# nrf9230_enga_cellrf register map
Vendor: Nordic Semiconductor; Series: nRF92; File version: 1
CPU: CM0 r0p0, little endian, no MPU, no FPU, 2 interrupt priority bits, 33 interrupts
Registers are 32-bit, read-write, reset 0x0 unless marked. A register's access mark holds for its fields unless they carry their own. Offsets are from the block's base; [hi:lo] are bit positions; lines under a group give offsets from that group; {n}, {i} and the like mark numbered series; 'fields as' and 'values as' point back to an identical list.

## SENSORADC — Sensor Analog to Digital Converter
Base 0x46046000
0x00 TASKS_START wo — Start the ADC and prepare the result buffer in RAM.
  [0] TASKS_START
    1=Trigger task
0x04 TASKS_STOP wo — Stop the ADC and terminate any on-going conversion.
  [0] TASKS_STOP
    1=Trigger task
0x08 TASKS_SAMPLE wo — Start ADC sampling. Depending on the mode selected, one or more samples will be taken.
  [0] TASKS_SAMPLE
    1=Trigger task
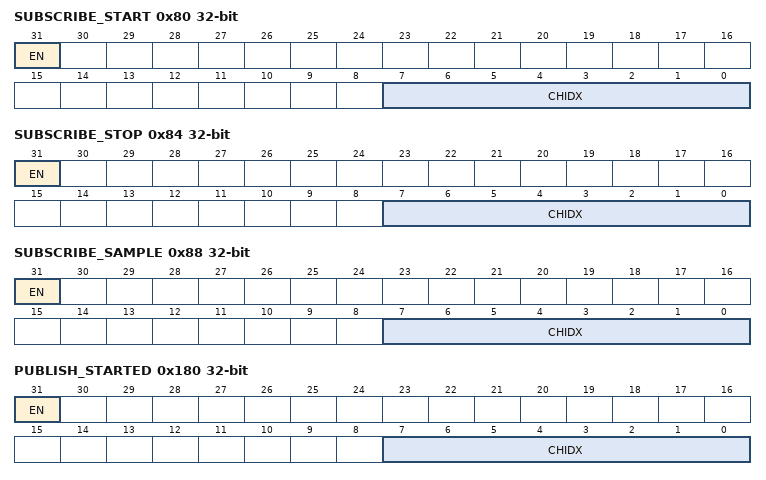
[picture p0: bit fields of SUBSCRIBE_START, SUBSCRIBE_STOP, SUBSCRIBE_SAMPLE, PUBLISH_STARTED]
0x80 SUBSCRIBE_START — Subscribe configuration for task START
  [31] EN
    0=Disabled (Disable subscription); 1=Enabled (Enable subscription)
  [7:0] CHIDX — DPPI channel that task START will subscribe to
0x84 SUBSCRIBE_STOP — Subscribe configuration for task STOP
  [31] EN
    values as SUBSCRIBE_START.EN
  [7:0] CHIDX — DPPI channel that task STOP will subscribe to
0x88 SUBSCRIBE_SAMPLE — Subscribe configuration for task SAMPLE
  [31] EN
    values as SUBSCRIBE_START.EN
  [7:0] CHIDX — DPPI channel that task SAMPLE will subscribe to
0x100 EVENTS_STARTED — The ADC has started.
  [0] EVENTS_STARTED
    0=NotGenerated (Event not generated); 1=Generated (Event generated)
0x104 EVENTS_STOPPED — The ADC has stopped.
  [0] EVENTS_STOPPED
    values as EVENTS_STARTED.EVENTS_STARTED
0x108 EVENTS_SAMPLEDONE — A single conversion has been completed and the corresponding result has been stored in RESULTN and RESULTP registers.
  [0] EVENTS_SAMPLEDONE
    values as EVENTS_STARTED.EVENTS_STARTED
0x10C EVENTS_AVERAGEDONE — The averaging has been completed and the corresponding, averaged result has been stored in AVERAGEN and AVERAGEP registers.
  [0] EVENTS_AVERAGEDONE
    values as EVENTS_STARTED.EVENTS_STARTED
0x110 EVENTS_DMANOTFULL — A result of last A/D conversion has been transferred to RAM and there is still space in RAM
  [0] EVENTS_DMANOTFULL
    values as EVENTS_STARTED.EVENTS_STARTED
0x114 EVENTS_DMADONE — A result of last A/D conversion has been transferred to RAM.
  [0] EVENTS_DMADONE
    values as EVENTS_STARTED.EVENTS_STARTED
0x118 EVENTS_DMAEND — The ADC has filled up the result buffer in RAM
  [0] EVENTS_DMAEND
    values as EVENTS_STARTED.EVENTS_STARTED
0x180 PUBLISH_STARTED — Publish configuration for event STARTED
  [31] EN
    0=Disabled (Disable publishing); 1=Enabled (Enable publishing)
  [7:0] CHIDX — DPPI channel that event STARTED will publish to
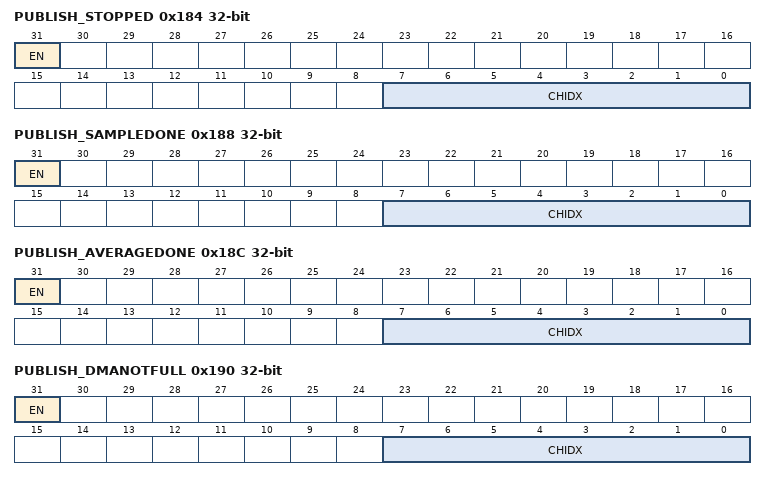
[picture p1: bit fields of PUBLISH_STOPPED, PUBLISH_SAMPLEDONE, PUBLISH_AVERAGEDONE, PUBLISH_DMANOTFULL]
0x184 PUBLISH_STOPPED — Publish configuration for event STOPPED
  [31] EN
    values as PUBLISH_STARTED.EN
  [7:0] CHIDX — DPPI channel that event STOPPED will publish to
0x188 PUBLISH_SAMPLEDONE — Publish configuration for event SAMPLEDONE
  [31] EN
    values as PUBLISH_STARTED.EN
  [7:0] CHIDX — DPPI channel that event SAMPLEDONE will publish to
0x18C PUBLISH_AVERAGEDONE — Publish configuration for event AVERAGEDONE
  [31] EN
    values as PUBLISH_STARTED.EN
  [7:0] CHIDX — DPPI channel that event AVERAGEDONE will publish to
0x190 PUBLISH_DMANOTFULL — Publish configuration for event DMANOTFULL
  [31] EN
    values as PUBLISH_STARTED.EN
  [7:0] CHIDX — DPPI channel that event DMANOTFULL will publish to
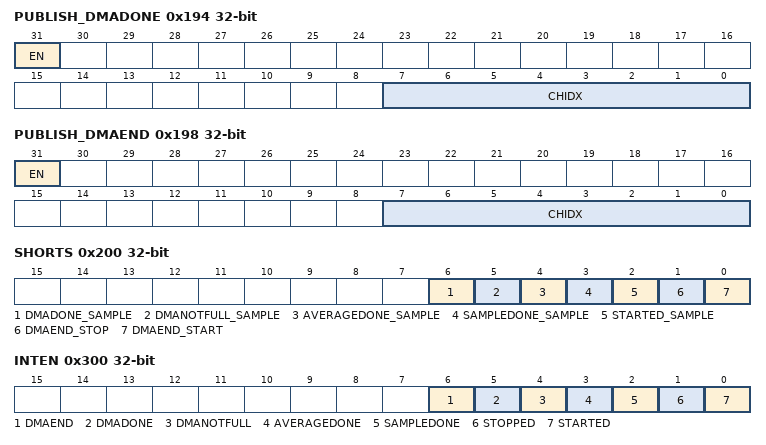
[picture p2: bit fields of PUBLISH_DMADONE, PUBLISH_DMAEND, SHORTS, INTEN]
0x194 PUBLISH_DMADONE — Publish configuration for event DMADONE
  [31] EN
    values as PUBLISH_STARTED.EN
  [7:0] CHIDX — DPPI channel that event DMADONE will publish to
0x198 PUBLISH_DMAEND — Publish configuration for event DMAEND
  [31] EN
    values as PUBLISH_STARTED.EN
  [7:0] CHIDX — DPPI channel that event DMAEND will publish to
0x200 SHORTS — Shortcuts between local events and tasks
  [all] fields
    0=Disabled (Disable shortcut); 1=Enabled (Enable shortcut)
  [6] DMADONE_SAMPLE — Shortcut between event DMADONE and task SAMPLE
  [5] DMANOTFULL_SAMPLE — Shortcut between event DMANOTFULL and task SAMPLE
  [4] AVERAGEDONE_SAMPLE — Shortcut between event AVERAGEDONE and task SAMPLE
  [3] SAMPLEDONE_SAMPLE — Shortcut between event SAMPLEDONE and task SAMPLE
  [2] STARTED_SAMPLE — Shortcut between event STARTED and task SAMPLE
  [1] DMAEND_STOP — Shortcut between event DMAEND and task STOP
  [0] DMAEND_START — Shortcut between event DMAEND and task START
0x300 INTEN — Enable or disable interrupt
  [all] fields
    0=Disabled; 1=Enabled
  [6] DMAEND — Enable or disable interrupt for event DMAEND
  [5] DMADONE — Enable or disable interrupt for event DMADONE
  [4] DMANOTFULL — Enable or disable interrupt for event DMANOTFULL
  [3] AVERAGEDONE — Enable or disable interrupt for event AVERAGEDONE
  [2] SAMPLEDONE — Enable or disable interrupt for event SAMPLEDONE
  [1] STOPPED — Enable or disable interrupt for event STOPPED
  [0] STARTED — Enable or disable interrupt for event STARTED
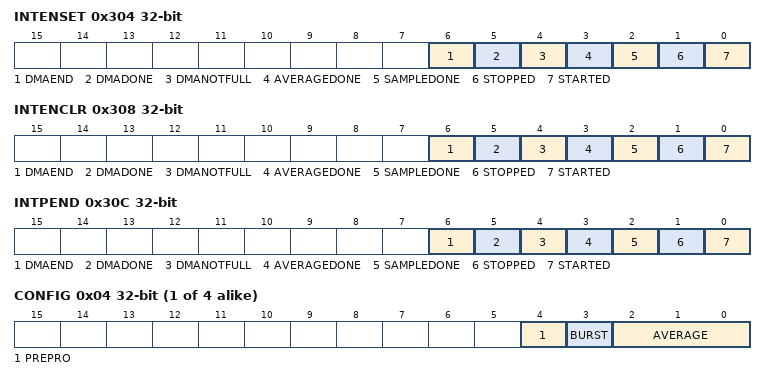
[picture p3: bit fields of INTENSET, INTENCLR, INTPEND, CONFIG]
0x304 INTENSET — Enable interrupt
  [all] fields
    on read: 0=Disabled (Read: Disabled); 1=Enabled (Read: Enabled) | on write: 1=Set (Enable)
  [6] DMAEND — Write '1' to enable interrupt for event DMAEND
  [5] DMADONE — Write '1' to enable interrupt for event DMADONE
  [4] DMANOTFULL — Write '1' to enable interrupt for event DMANOTFULL
  [3] AVERAGEDONE — Write '1' to enable interrupt for event AVERAGEDONE
  [2] SAMPLEDONE — Write '1' to enable interrupt for event SAMPLEDONE
  [1] STOPPED — Write '1' to enable interrupt for event STOPPED
  [0] STARTED — Write '1' to enable interrupt for event STARTED
0x308 INTENCLR — Disable interrupt
  [all] fields
    on read: 0=Disabled (Read: Disabled); 1=Enabled (Read: Enabled) | on write: 1=Clear (Disable)
  [6] DMAEND — Write '1' to disable interrupt for event DMAEND
  [5] DMADONE — Write '1' to disable interrupt for event DMADONE
  [4] DMANOTFULL — Write '1' to disable interrupt for event DMANOTFULL
  [3] AVERAGEDONE — Write '1' to disable interrupt for event AVERAGEDONE
  [2] SAMPLEDONE — Write '1' to disable interrupt for event SAMPLEDONE
  [1] STOPPED — Write '1' to disable interrupt for event STOPPED
  [0] STARTED — Write '1' to disable interrupt for event STARTED
0x30C INTPEND ro — Pending interrupts
  [all] fields
    on read: 0=NotPending (Read: Not pending); 1=Pending (Read: Pending)
  [6] DMAEND — Read pending status of interrupt for event DMAEND
  [5] DMADONE — Read pending status of interrupt for event DMADONE
  [4] DMANOTFULL — Read pending status of interrupt for event DMANOTFULL
  [3] AVERAGEDONE — Read pending status of interrupt for event AVERAGEDONE
  [2] SAMPLEDONE — Read pending status of interrupt for event SAMPLEDONE
  [1] STOPPED — Read pending status of interrupt for event STOPPED
  [0] STARTED — Read pending status of interrupt for event STARTED
0x400 STATUS ro — ADC status
  [2:0] CURRSTATE — Current FSM state. More and less for debugging.
    0=Stopped (Unspecified); 1=Started (Unspecified); 2=Idle (Unspecified); 3=Settling (Unspecified); 4=Conversion (Unspecified); 5=Result (Unspecified)
0x500 ENABLE — Set value for output signal Enable
  [0] ENABLE — This register has no other function than defining the value on enable output. Check the usage of this signal from integration level.
    0=Disabled; 1=Enabled
0x504 ICTRL — Adjust charge current
  [3:0] ICTRL — Adjust charge current (thermometer coding).
    0=Min (Capacitor charge current is 0 * Uin/R (reset value)); 6=Default (Capacitor charge current is 6/12 * Uin/R (default)); 15=Max (Capacitor charge current is 15/12 * Uin/R)
0x508 SETTLINGTIME — Settling time selection
  [2:0] TIME — Settling time selection.
    0=Time1us (1 us (123 * 1 core clock cycles)); 1=Time2us (2 us (123 * 2 core clock cycles)); 2=Time4us (4 us (123 * 4 core clock cycles)); 3=Time8us (8 us (123 * 8 core clock cycles)); 4=Time16us (16 us (123 * 16 core clock cycles)); 5=Time32us (32 us (123 * 32 core clock cycles)); 6=Time64us (64 us (123 * 64 core clock cycles)); 7=Time128us (128 us (123 * 128 core clock cycles))
0x50C CONVCYCLES — Conversion cycles (i.e. accuracy)
  [15:0] CYCLES — Conversion cycles (i.e. accuracy).
    0xFFFF=Max (65535: 65535 core clock cycles)
0x510 CONVMODE — Conversion mode selection
  [1:0] MODE — Conversion mode selection.
    0=One-shot mode; 1=Pure one-shot mode; 2=Continuous mode
{0x514+8i} CH[{i}] (i=0..3) group — Unspecified
  0x00 INSEL — Description cluster: Input pin selection for CH[n]
    [15:0] INSEL — Input pin selection for channel n. Please only use values listed here. Other values will cause two inputs to be weakly shorted together.
      0=Nothing is connected; 1=VinAo0; 2=VinAo1; 4=VinAo2; 8=VinAo3; 16=Vin0; 32=Vin1; 64=Vin2; 128=Vin3; 0x200=Vref2 (750 mV); 0x400=Vref0 = (300 mV); 0x800=Vref1 = (600 mV); 0x1000=ATB0_1V8; 0x2000=ATB1_1V8; 0x4000=WATB2_1V8; 0x8000=WATB3_1V8
  0x04 CONFIG — Description cluster: Configuration for CH[n]
    [4] PREPRO — Pre-processing mode. When the pre-processing mode is selected, P results are pre-processed before being stored in RESULTP/AVERAGEP register.
      0=Normal operation; 1=Pre-processing mode
    [3] BURST — Burst mode. Reduces settling time to a minimum between conversions when averaging or continuous mode is enabled.
      0=Normal operation; 1=Burst mode enabled
    [2:0] AVERAGE — Averaging configuration.
      0=Disabled (Averaging disabled); 1=Averaging by 2; 2=Averaging by 4; 3=Averaging by 8; 4=Averaging by 16; 5=Averaging by 32; 6=Averaging by 64; 7=Averaging by 128
0x554 RESULTN ro — Result N of last A/D conversion
  [15:0] RESULT — Result N of last A/D conversion. The value is updated for every completed conversion. The value is in unsigned format.
0x558 RESULTP ro — Result P of last A/D conversion
  [15:0] RESULT — Result P of last A/D conversion. The value is updated for every completed conversion. The value is in unsigned format.
0x55C AVERAGEN ro — Result N of last averaged A/D conversion
  [15:0] AVERAGE — Result N of last averaged A/D conversion. The value is updated for every completed averaged conversion. The value is in unsigned format.
0x560 AVERAGEP ro — Result P of last averaged A/D conversion
  [15:0] AVERAGE — Result P of last averaged A/D conversion. The value is updated for every completed averaged conversion. The value is in unsigned format.
0x564 RESETCONFIG — Reset configuration
  [0] CONFIG — Backdoor for core part reset.
    0=NoEffect; 1=CoreReset (Debug only: Core is reset asynchronously when IP is not active. Note that this can cause reset doman crossing (RDC) violation.)
0x568 SPARE
  [3:0] SPARE
0x56C ATB0CFG — Configuration for ATB 0 connection. Access to this register is only allowed when dftEnable input is 1.
  [0] ATB0CFG — Configuration for ATB 0 connection.
    0=Nothing is connected to ATB0_1V8; 1=Vref1 is connected to ATB0_1V8
0x570 ATB1CFG — Configuration for ATB 1 connection. Access to this register is only allowed when dftEnable input is 1.
  [2:0] ATB1CFG — Configuration for ATB 1 connection.
    {v}=Nothing{v} (Nothing is connected to ATB1_1V8) (v=0..4); 5=Vref1 (Connect Vref1 to ATB1_1V8); 6=Vc (Connect Vc to ATB1_1V8); 7=Vr (Connect Vr to ATB1_1V8)
0x574 DTB0CFG — Configuration for DTB 0 connection. Access to this register is only allowed when dftEnable input is 1.
  [0] DTB0CFG — Configuration for DTB 0 connection.
    0=Nothing is connected to DTB_SENSORADC_0V8[0]; 1=FOUT is connected to DTB_SENSORADC_0V8[0]
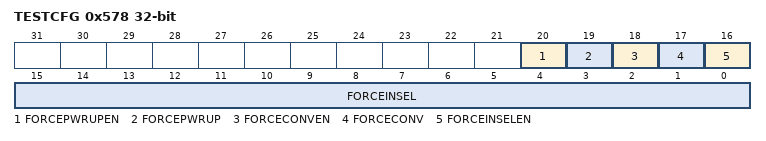
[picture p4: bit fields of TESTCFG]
0x578 TESTCFG — Test configuration register. Access to this register is only allowed when dftEnable input is 1.
  [20] FORCEPWRUPEN — FORCEPWRUPEN enables FORCEPWRUP register.
  [19] FORCEPWRUP — FORCEPWRUP is forced to PWRUP_SENSORADC_AO_0V8 when FORCEPWRUPEN is 1.
  [18] FORCECONVEN — FORCECONVEN enables FORCECONV register.
  [17] FORCECONV — FORCECONV is forced to SENSORADC_ENABLE_0V8 when FORCECONVEN is 1.
  [16] FORCEINSELEN — FORCEINSELEN is enables FORCEINSEL register.
  [15:0] FORCEINSEL — FORCEINSEL[15:0] is forced to SENSORADC_INSEL_0V8 when FORCEINSEL[16] is 1.
0x62C RESULT group — RESULT EasyDMA channel
  0x00 PTR — Data pointer
  0x04 MAXCNT — Maximum number of buffer words to transfer
    [13:0] MAXCNT
  0x08 AMOUNT ro — Number of buffer words transferred since last START
    [13:0] AMOUNT — Number of buffer words transferred since last START.

## Notices in the file
Copyright (c) 2010 - 2024, Nordic Semiconductor ASA
All rights reserved.
Redistribution and use in source and binary forms, with or without modification,
are permitted provided that the following conditions are met:
1. Redistributions of source code must retain the above copyright notice, this
list of conditions and the following disclaimer.
2. Redistributions in binary form, except as embedded into a Nordic
Semiconductor ASA integrated circuit in a product or a software update for
such product, must reproduce the above copyright notice, this list of
conditions and the following disclaimer in the documentation and/or other
materials provided with the distribution.
3. Neither the name of Nordic Semiconductor ASA nor the names of its
contributors may be used to endorse or promote products derived from this
software without specific prior written permission.
4. This software, with or without modification, must only be used with a
Nordic Semiconductor ASA integrated circuit.
5. Any software provided in binary form under this license must not be reverse
engineered, decompiled, modified and/or disassembled.
THIS SOFTWARE IS PROVIDED BY NORDIC SEMICONDUCTOR ASA "AS IS" AND ANY EXPRESS
OR IMPLIED WARRANTIES, INCLUDING, BUT NOT LIMITED TO, THE IMPLIED WARRANTIES
OF MERCHANTABILITY, NONINFRINGEMENT, AND FITNESS FOR A PARTICULAR PURPOSE ARE
DISCLAIMED. IN NO EVENT SHALL NORDIC SEMICONDUCTOR ASA OR CONTRIBUTORS BE
LIABLE FOR ANY DIRECT, INDIRECT, INCIDENTAL, SPECIAL, EXEMPLARY, OR
CONSEQUENTIAL DAMAGES (INCLUDING, BUT NOT LIMITED TO, PROCUREMENT OF SUBSTITUTE
GOODS OR SERVICES; LOSS OF USE, DATA, OR PROFITS; OR BUSINESS INTERRUPTION)
HOWEVER CAUSED AND ON ANY THEORY OF LIABILITY, WHETHER IN CONTRACT, STRICT
LIABILITY, OR TORT (INCLUDING NEGLIGENCE OR OTHERWISE) ARISING IN ANY WAY OUT
OF THE USE OF THIS SOFTWARE, EVEN IF ADVISED OF THE POSSIBILITY OF SUCH DAMAGE.
